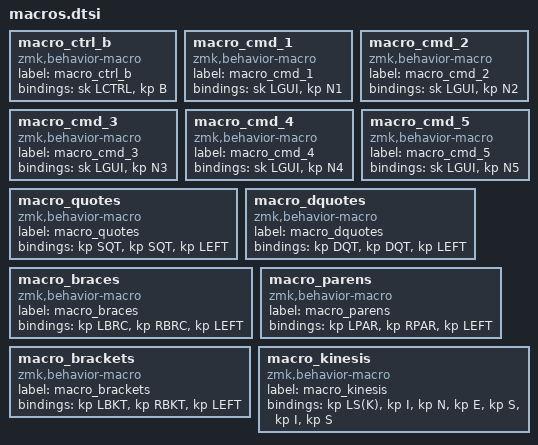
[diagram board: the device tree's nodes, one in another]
macro_ctrl_b: macro_ctrl_b{
compatible = "zmk,behavior-macro";
label = "macro_ctrl_b";
#binding-cells = <0>;
bindings = <&sk LCTRL>, <&kp B>;
};
macro_cmd_1: macro_cmd_1{
compatible = "zmk,behavior-macro";
label = "macro_cmd_1";
#binding-cells = <0>;
bindings = <&sk LGUI>, <&kp N1>;
};
macro_cmd_2: macro_cmd_2{
compatible = "zmk,behavior-macro";
label = "macro_cmd_2";
#binding-cells = <0>;
bindings = <&sk LGUI>, <&kp N2>;
};
macro_cmd_3: macro_cmd_3{
compatible = "zmk,behavior-macro";
label = "macro_cmd_3";
#binding-cells = <0>;
bindings = <&sk LGUI>, <&kp N3>;
};
macro_cmd_4: macro_cmd_4{
compatible = "zmk,behavior-macro";
label = "macro_cmd_4";
#binding-cells = <0>;
bindings = <&sk LGUI>, <&kp N4>;
};
macro_cmd_5: macro_cmd_5{
compatible = "zmk,behavior-macro";
label = "macro_cmd_5";
#binding-cells = <0>;
bindings = <&sk LGUI>, <&kp N5>;
};
macro_quotes: macro_quotes{
compatible = "zmk,behavior-macro";
label = "macro_quotes";
#binding-cells = <0>;
bindings = <&kp SQT>, <&kp SQT>, <&kp LEFT>;
};
macro_dquotes: macro_dquotes{
compatible = "zmk,behavior-macro";
label = "macro_dquotes";
#binding-cells = <0>;
bindings = <&kp DQT>, <&kp DQT>, <&kp LEFT>;
};
macro_braces: macro_braces{
compatible = "zmk,behavior-macro";
label = "macro_braces";
#binding-cells = <0>;
bindings = <&kp LBRC>, <&kp RBRC>, <&kp LEFT>;
};
macro_parens: macro_parens{
compatible = "zmk,behavior-macro";
label = "macro_parens";
#binding-cells = <0>;
bindings = <&kp LPAR>, <&kp RPAR>, <&kp LEFT>;
};
macro_brackets: macro_brackets{
compatible = "zmk,behavior-macro";
label = "macro_brackets";
#binding-cells = <0>;
bindings = <&kp LBKT>, <&kp RBKT>, <&kp LEFT>;
};
macro_kinesis: macro_kinesis{
compatible = "zmk,behavior-macro";
label = "macro_kinesis";
#binding-cells = <0>;
bindings = <&kp LS(K)>, <&kp I>, <&kp N>, <&kp E>, <&kp S>, <&kp I>, <&kp S>;
};
